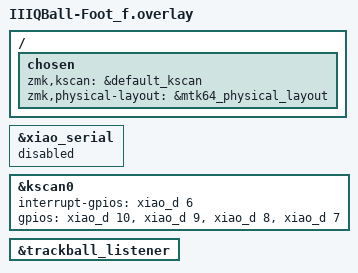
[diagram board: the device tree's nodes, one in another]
#include "IIIQBall-Foot.dtsi"
#include "IIIQBall-Foot_trackball.dtsi"

&xiao_serial {
    status = "disabled";
};

/ {
    chosen {
        zmk,kscan = &default_kscan;
        zmk,physical-layout = &mtk64_physical_layout;
    };
};

&kscan0 {
    interrupt-gpios = <&xiao_d 6 (GPIO_ACTIVE_HIGH | GPIO_PULL_DOWN)>;
    gpios = 
        <&xiao_d 10 GPIO_ACTIVE_HIGH>,
        <&xiao_d 9  GPIO_ACTIVE_HIGH>,
        <&xiao_d 8  GPIO_ACTIVE_HIGH>,
        <&xiao_d 7  GPIO_ACTIVE_HIGH>;
};

&trackball_listener {
    status = "okay";  
};
